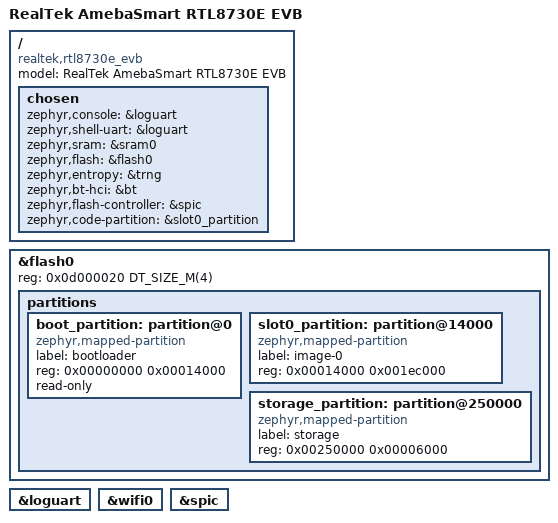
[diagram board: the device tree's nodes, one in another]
/*
 * Copyright (c) 2024 Realtek Semiconductor Corp.
 *
 * SPDX-License-Identifier: Apache-2.0
 */

/dts-v1/;

#include <realtek/amebasmart/amebasmart_hp.dtsi>
#include "rtl8730e_evb-pinctrl.dtsi"

/ {
	model = "RealTek AmebaSmart RTL8730E EVB";
	compatible = "realtek,rtl8730e_evb";

	chosen {
		zephyr,console = &loguart;
		zephyr,shell-uart = &loguart;
		zephyr,sram = &sram0;
		zephyr,flash = &flash0;
		zephyr,entropy = &trng;
		zephyr,bt-hci = &bt;
		zephyr,flash-controller = &spic;
		zephyr,code-partition = &slot0_partition;
	};
};

&flash0 {
	reg = <0x0d000020 DT_SIZE_M(4)>;
	ranges = <0x0 0x0d000020 DT_SIZE_M(4)>;

	partitions {
		ranges;
		#address-cells = <1>;
		#size-cells = <1>;

		boot_partition: partition@0 {
			compatible = "zephyr,mapped-partition";
			label = "bootloader";
			reg = <0x00000000 0x00014000>;
			read-only;
		};

		slot0_partition: partition@14000 {
			compatible = "zephyr,mapped-partition";
			label = "image-0";
			reg = <0x00014000 0x001ec000>;
		};

		storage_partition: partition@250000 {
			compatible = "zephyr,mapped-partition";
			label = "storage";
			reg = <0x00250000 0x00006000>;
		};
	};
};

&loguart {
	status = "okay";
};

&wifi0 {
	status = "okay";
};

&spic {
	status = "okay";
};
